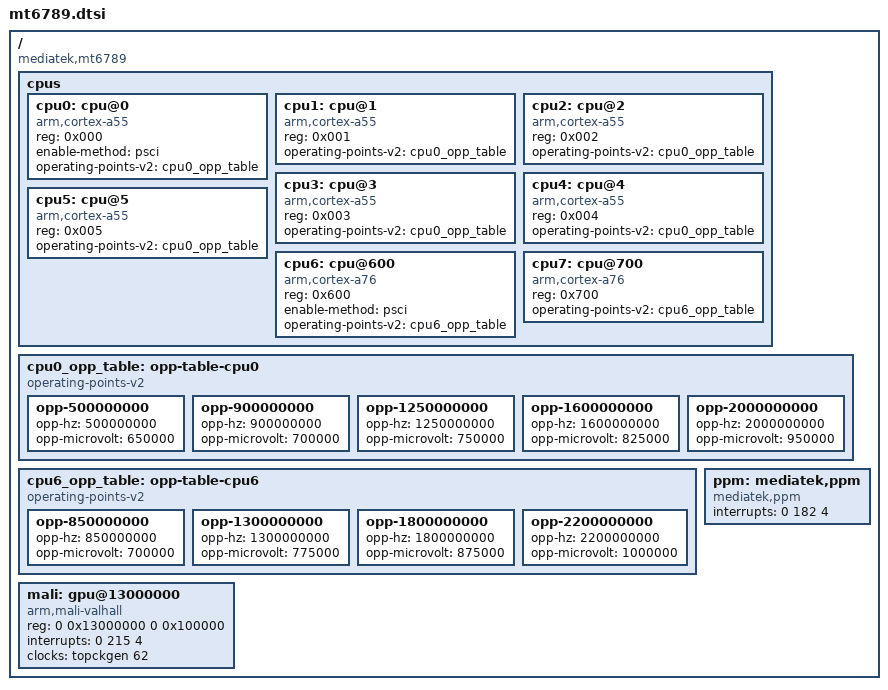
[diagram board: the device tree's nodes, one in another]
// SPDX-License-Identifier: GPL-2.0
/*
 * MediaTek MT6789 (Helio G99 / G99 Ultimate) Device Tree Source
 * Reference: Poco M5 (Rock) / Infinix Note 12 2023 / Tecno Camon 20 Pro
 * Source: MiCode/Xiaomi_Kernel_OpenSource (rock-s-oss)
 */

/ {
	compatible = "mediatek,mt6789";
	#address-cells = <2>;
	#size-cells = <2>;

	cpus {
		#address-cells = <1>;
		#size-cells = <0>;

		/* Little Cluster (Cores 0-5): 6x Cortex-A55 up to 2.0 GHz */
		cpu0: cpu@0 {
			device_type = "cpu";
			compatible = "arm,cortex-a55";
			reg = <0x000>;
			enable-method = "psci";
			operating-points-v2 = <&cpu0_opp_table>;
		};
		cpu1: cpu@1 {
			device_type = "cpu";
			compatible = "arm,cortex-a55";
			reg = <0x001>;
			operating-points-v2 = <&cpu0_opp_table>;
		};
		cpu2: cpu@2 {
			device_type = "cpu";
			compatible = "arm,cortex-a55";
			reg = <0x002>;
			operating-points-v2 = <&cpu0_opp_table>;
		};
		cpu3: cpu@3 {
			device_type = "cpu";
			compatible = "arm,cortex-a55";
			reg = <0x003>;
			operating-points-v2 = <&cpu0_opp_table>;
		};
		cpu4: cpu@4 {
			device_type = "cpu";
			compatible = "arm,cortex-a55";
			reg = <0x004>;
			operating-points-v2 = <&cpu0_opp_table>;
		};
		cpu5: cpu@5 {
			device_type = "cpu";
			compatible = "arm,cortex-a55";
			reg = <0x005>;
			operating-points-v2 = <&cpu0_opp_table>;
		};

		/* Big Cluster (Cores 6-7): 2x Cortex-A76 up to 2.2 GHz */
		cpu6: cpu@600 {
			device_type = "cpu";
			compatible = "arm,cortex-a76";
			reg = <0x600>;
			enable-method = "psci";
			operating-points-v2 = <&cpu6_opp_table>;
		};
		cpu7: cpu@700 {
			device_type = "cpu";
			compatible = "arm,cortex-a76";
			reg = <0x700>;
			operating-points-v2 = <&cpu6_opp_table>;
		};
	};

	cpu0_opp_table: opp-table-cpu0 {
		compatible = "operating-points-v2";
		opp-500000000  { opp-hz = /bits/ 64 <500000000>;  opp-microvolt = <650000>; };
		opp-900000000  { opp-hz = /bits/ 64 <900000000>;  opp-microvolt = <700000>; };
		opp-1250000000 { opp-hz = /bits/ 64 <1250000000>; opp-microvolt = <750000>; };
		opp-1600000000 { opp-hz = /bits/ 64 <1600000000>; opp-microvolt = <825000>; };
		opp-2000000000 { opp-hz = /bits/ 64 <2000000000>; opp-microvolt = <950000>; };
	};

	cpu6_opp_table: opp-table-cpu6 {
		compatible = "operating-points-v2";
		opp-850000000  { opp-hz = /bits/ 64 <850000000>;  opp-microvolt = <700000>; };
		opp-1300000000 { opp-hz = /bits/ 64 <1300000000>; opp-microvolt = <775000>; };
		opp-1800000000 { opp-hz = /bits/ 64 <1800000000>; opp-microvolt = <875000>; };
		opp-2200000000 { opp-hz = /bits/ 64 <2200000000>; opp-microvolt = <1000000>; };
	};

	/* ARM Mali-G57 MC2 (Valhall v1) @ 950 MHz */
	mali: gpu@13000000 {
		compatible = "arm,mali-valhall", "arm,mali-g57";
		reg = <0 0x13000000 0 0x100000>;
		interrupts = <0 215 4>;
		clocks = <&topckgen 62>;
		clock-names = "mali_core";
	};

	ppm: mediatek,ppm {
		compatible = "mediatek,ppm";
		interrupts = <0 182 4>;
	};
};
